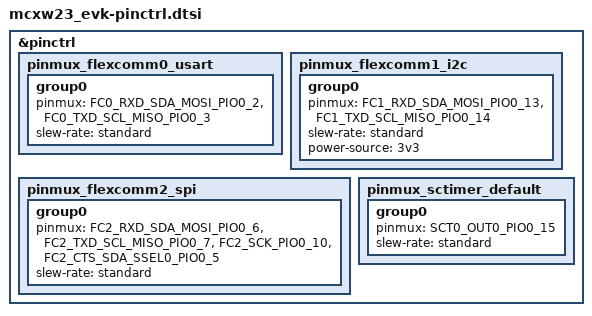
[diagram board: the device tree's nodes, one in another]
/*
 * Copyright 2025 NXP
 *
 * SPDX-License-Identifier: Apache-2.0
 */

#include <nxp/mcx/MCXW236BIHNAR-pinctrl.h>

&pinctrl {
	/* Configures pin routing and optionally pin electrical features. */
	pinmux_flexcomm0_usart: pinmux_flexcomm0_usart {
		group0 {
			pinmux = <FC0_RXD_SDA_MOSI_PIO0_2>,
				<FC0_TXD_SCL_MISO_PIO0_3>;
			slew-rate = "standard";
		};
	};

	/* Configures pin routing and optionally pin electrical features. */
	pinmux_flexcomm1_i2c: pinmux_flexcomm1_i2c {
		group0 {
			pinmux = <FC1_RXD_SDA_MOSI_PIO0_13>,
				<FC1_TXD_SCL_MISO_PIO0_14>;
			slew-rate = "standard";
			power-source = "3v3";
		};
	};

	pinmux_flexcomm2_spi: pinmux_flexcomm2_spi {
		group0 {
			pinmux = <FC2_RXD_SDA_MOSI_PIO0_6>,
				<FC2_TXD_SCL_MISO_PIO0_7>,
				<FC2_SCK_PIO0_10>,
				<FC2_CTS_SDA_SSEL0_PIO0_5>;
			slew-rate = "standard";
		};
	};

	pinmux_sctimer_default: pinmux_sctimer_default {
		group0 {
			pinmux = <SCT0_OUT0_PIO0_15>;
			slew-rate = "standard";
		};
	};
};
